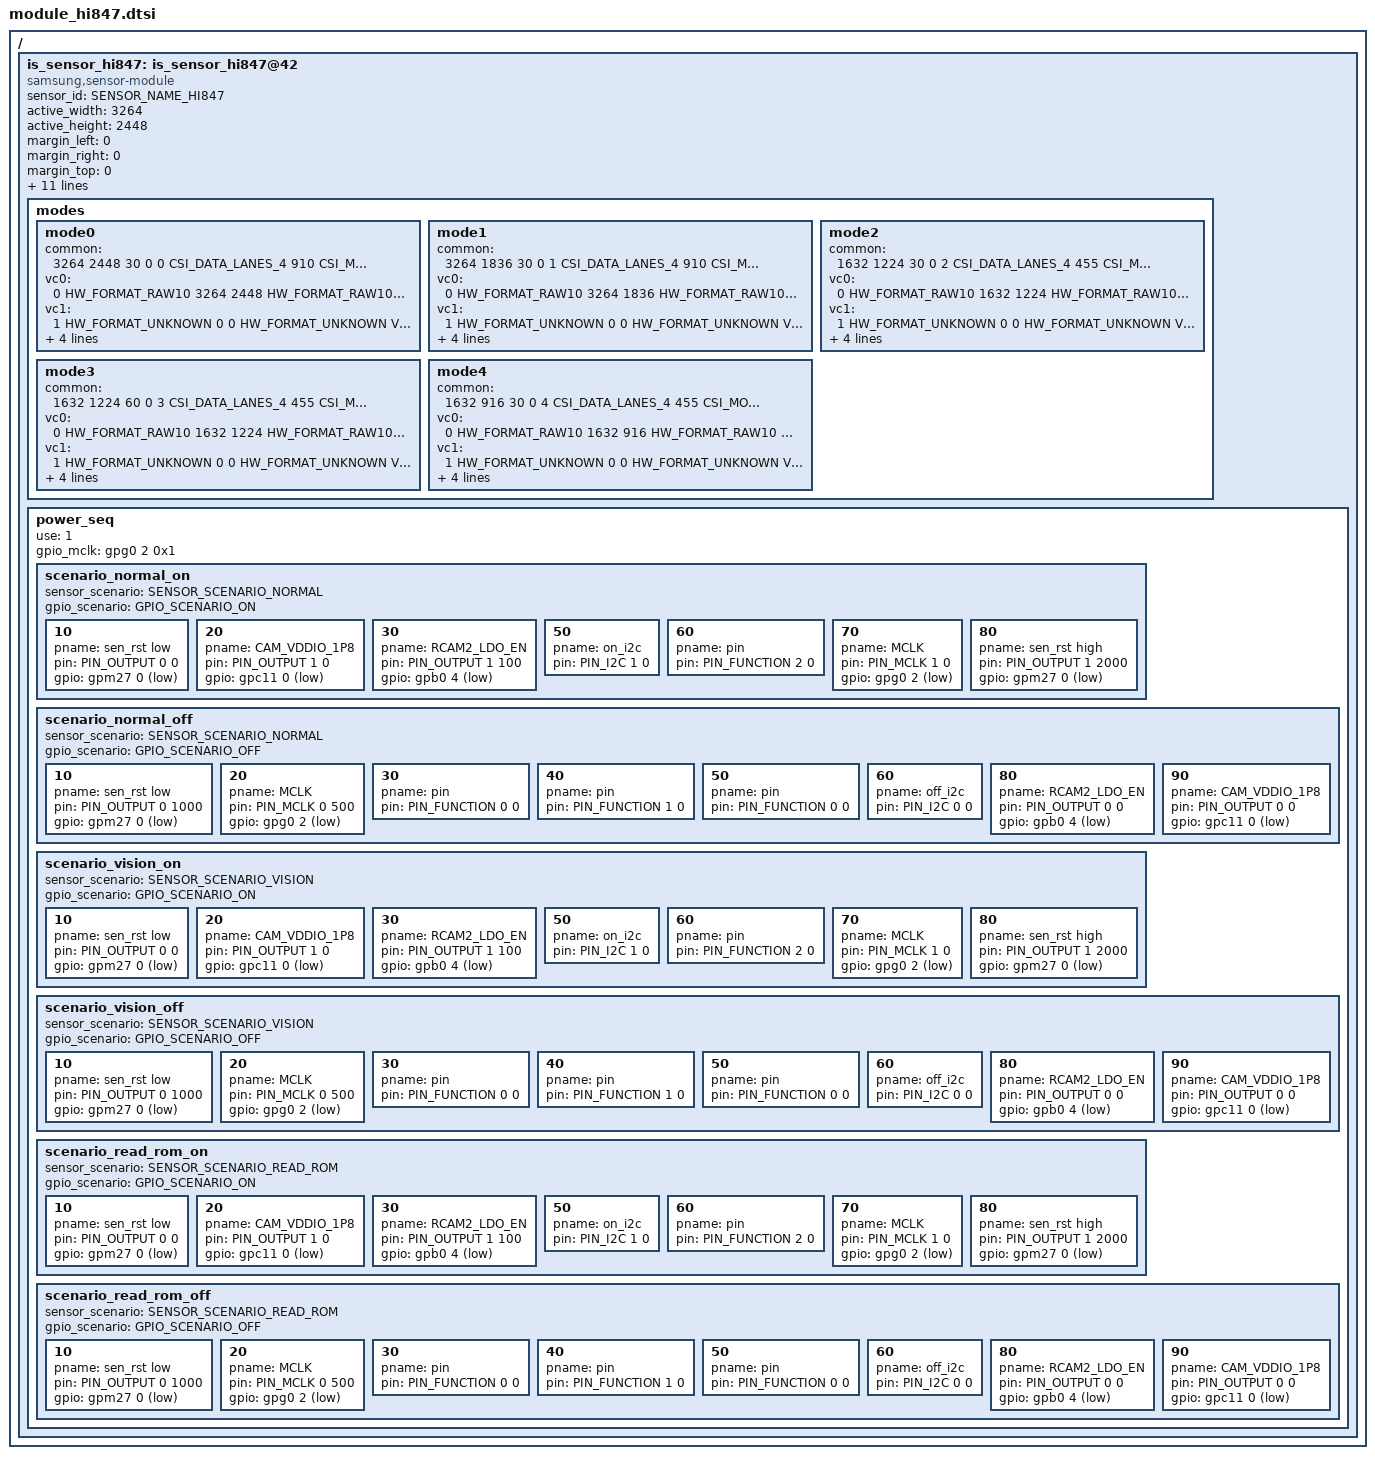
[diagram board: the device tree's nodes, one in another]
/*
 * SAMSUNG EXYNOSxxxx board camera device tree source
 *
 * Copyright (c) 2023 Samsung Electronics Co., Ltd.
 *		http://www.samsung.com
 *
 * This program is free software; you can redistribute it and/or modify
 * it under the terms of the GNU General Public License version 2 as
 * published by the Free Software Foundation.
 */

#include <dt-bindings/camera/exynos_is_dt.h>

/ {
	fragment@camera {
		target-path = "/";
		__overlay__ {
			is_sensor_hi847: is_sensor_hi847@42 {
				compatible = "samsung,sensor-module";

				/* common */
				sensor_id = <SENSOR_NAME_HI847>;
				active_width = <3264>;
				active_height = <2448>;
				margin_left = <0>;
				margin_right = <0>;
				margin_top = <0>;
				margin_bottom = <0>;
				max_framerate = <60>;
				bitwidth = <10>;
				use_retention_mode = <SENSOR_RETENTION_UNSUPPORTED>;
				sensor_maker = "HYNIX";
				sensor_name = "HI847";
				setfile_name = "setfile_hi847.bin";
				//pinning_setfile;
				//preload_setfile;

				status = "okay";

				/* vendor */
				rom_type = <3>; /* ROM_TYPE_OTPROM */
				rom_id = <2>;
				rom_cal_index = <0>;
#if 0
				vc_extra {
					/* ex) statX = <stat_type, sensor_mode, max_width, max_height, max_element> */
					/* VC_BUF_DATA_TYPE_SENSOR_STAT1 */
					stat0 = </*VC_STAT_TYPE_TAIL_FOR_3HDR_IMX_2_STAT0*/ 602    /*VC_SENSOR_MODE_3HDR_IMX_2*/ 602 4080 2 1>;
					/* VC_BUF_DATA_TYPE_GENERAL_STAT1 */
					stat1 = </* not available */>;
					/* VC_BUF_DATA_TYPE_SENSOR_STAT2 */
					stat2 = </*VC_STAT_TYPE_TAIL_FOR_3HDR_IMX_2_STAT1*/ 603    /*VC_SENSOR_MODE_3HDR_IMX_2*/ 602 4080 3 1>;
					/* VC_BUF_DATA_TYPE_GENERAL_STAT2 */
					stat3 = </* not available */>;
				};
#endif
				/*
				* [Mode Information]
				*
				* Reference File : Hi-847_setting_v1.0.0.69_SEC12_20220124.xlsx
				*
				*  [ 0 ] 3264 x 2448(4:3)      @30,  MIPI lane: 4, MIPI data rate(Mbps/lane):  910, Mclk(Mhz): 26
				*  [ 1 ] 3264 x 1836(16:9)      @30,  MIPI lane: 4, MIPI data rate(Mbps/lane):  910, Mclk(Mhz): 26
				*  [ 2 ] 1632 x 1224(4:3)      @30,  MIPI lane: 4, MIPI data rate(Mbps/lane):  455, Mclk(Mhz): 26
				*  [ 3 ] 1632 x 1224(4:3)      @60,  MIPI lane: 4, MIPI data rate(Mbps/lane):  455, Mclk(Mhz): 26
				*  [ 4 ] 1632 x 916(16:9)      @30,  MIPI lane: 4, MIPI data rate(Mbps/lane):  455, Mclk(Mhz): 26
				*/

				/* sensor modes */
				modes {
						/* common = <width, height, fps, settle, mode, lane, speed, interleave, lrte, pd_mode> */
						/* vcX = <map, hwformat, width, height, hwformat, type, width, height> */

					mode0 {/* A-1 */
						common = <3264 2448 30 0 0 CSI_DATA_LANES_4 910 CSI_MODE_VC_ONLY LRTE_DISABLE PD_NONE EX_NONE>;
						vc0 = </* in */ 0 HW_FORMAT_RAW10 3264 2448    /* out */ HW_FORMAT_RAW10 VC_NOTHING 3264 2448>;
						vc1 = </* in */ 1 HW_FORMAT_UNKNOWN 0 0        /* out */ HW_FORMAT_UNKNOWN VC_NOTHING 0 0>;
						vc2 = </* in */ 2 HW_FORMAT_UNKNOWN 0 0        /* out */ HW_FORMAT_UNKNOWN VC_NOTHING 0 0>; 
						vc3 = </* in */ 3 HW_FORMAT_UNKNOWN 0 0        /* out */ HW_FORMAT_UNKNOWN VC_NOTHING 0 0>;
					};
					mode1 {/* K-1 */
						common = <3264 1836 30 0 1 CSI_DATA_LANES_4 910 CSI_MODE_VC_ONLY LRTE_DISABLE PD_NONE>;
						vc0 = </* in */ 0 HW_FORMAT_RAW10 3264 1836    /* out */ HW_FORMAT_RAW10 VC_NOTHING 3264 1836>;
						vc1 = </* in */ 1 HW_FORMAT_UNKNOWN 0 0        /* out */ HW_FORMAT_UNKNOWN VC_NOTHING 0 0>;
						vc2 = </* in */ 2 HW_FORMAT_UNKNOWN 0 0        /* out */ HW_FORMAT_UNKNOWN VC_NOTHING 0 0>;
						vc3 = </* in */ 3 HW_FORMAT_UNKNOWN 0 0        /* out */ HW_FORMAT_UNKNOWN VC_NOTHING 0 0>;
					};
					mode2 {/* N-1 */
						common = <1632 1224 30 0 2 CSI_DATA_LANES_4 455 CSI_MODE_VC_ONLY LRTE_DISABLE PD_NONE>;
						vc0 = </* in */ 0 HW_FORMAT_RAW10 1632 1224    /* out */ HW_FORMAT_RAW10 VC_NOTHING 1632 1224>;
						vc1 = </* in */ 1 HW_FORMAT_UNKNOWN 0 0        /* out */ HW_FORMAT_UNKNOWN VC_NOTHING 0 0>;
						vc2 = </* in */ 2 HW_FORMAT_UNKNOWN 0 0        /* out */ HW_FORMAT_UNKNOWN VC_NOTHING 0 0>;
						vc3 = </* in */ 3 HW_FORMAT_UNKNOWN 0 0        /* out */ HW_FORMAT_UNKNOWN VC_NOTHING 0 0>;
					};
					mode3 {/* J-1 */
						common = <1632 1224 60 0 3 CSI_DATA_LANES_4 455 CSI_MODE_VC_ONLY LRTE_DISABLE PD_NONE>;
						vc0 = </* in */ 0 HW_FORMAT_RAW10 1632 1224    /* out */ HW_FORMAT_RAW10 VC_NOTHING 1632 1224>;
						vc1 = </* in */ 1 HW_FORMAT_UNKNOWN 0 0        /* out */ HW_FORMAT_UNKNOWN VC_NOTHING 0 0>;
						vc2 = </* in */ 2 HW_FORMAT_UNKNOWN 0 0        /* out */ HW_FORMAT_UNKNOWN VC_NOTHING 0 0>;
						vc3 = </* in */ 3 HW_FORMAT_UNKNOWN 0 0        /* out */ HW_FORMAT_UNKNOWN VC_NOTHING 0 0>;
					};
					mode4 {/* J-1 */
						common = <1632 916 30 0 4 CSI_DATA_LANES_4 455 CSI_MODE_VC_ONLY LRTE_DISABLE PD_NONE>;
						vc0 = </* in */ 0 HW_FORMAT_RAW10 1632 916    /* out */ HW_FORMAT_RAW10 VC_NOTHING 1632 916>;
						vc1 = </* in */ 1 HW_FORMAT_UNKNOWN 0 0        /* out */ HW_FORMAT_UNKNOWN VC_NOTHING 0 0>;
						vc2 = </* in */ 2 HW_FORMAT_UNKNOWN 0 0        /* out */ HW_FORMAT_UNKNOWN VC_NOTHING 0 0>;
						vc3 = </* in */ 3 HW_FORMAT_UNKNOWN 0 0        /* out */ HW_FORMAT_UNKNOWN VC_NOTHING 0 0>;
					};
				};

				power_seq {
					use = <1>;
					gpio_mclk = <&gpg0 2 0x1>;

					scenario_normal_on {
						sensor_scenario = <SENSOR_SCENARIO_NORMAL>;
						gpio_scenario = <GPIO_SCENARIO_ON>;

						/* A start node number should be over the 10 for reserved number 0~9. */
						/* pname = "name"; pin = <act value dealy voltage>; gpio = <gpx# # 0x1>; */
						10 { pname = "sen_rst low"; pin = <PIN_OUTPUT 0 0>; gpio = <&gpm27 0 0x1>; };
						20 { pname = "CAM_VDDIO_1P8"; pin = <PIN_OUTPUT 1 0>; gpio = <&gpc11 0 0x1>; };
						30 { pname = "RCAM2_LDO_EN"; pin = <PIN_OUTPUT 1 100>; gpio = <&gpb0 4 0x1>; };
						50 { pname = "on_i2c"; pin = <PIN_I2C 1 0>; };
						60 { pname = "pin"; pin = <PIN_FUNCTION 2 0>; };
						70 { pname = "MCLK"; pin = <PIN_MCLK 1 0>; gpio = <&gpg0 2 0x1>; };
						80 { pname = "sen_rst high"; pin = <PIN_OUTPUT 1 2000>; gpio = <&gpm27 0 0x1>; };
					};

					scenario_normal_off {
						sensor_scenario = <SENSOR_SCENARIO_NORMAL>;
						gpio_scenario = <GPIO_SCENARIO_OFF>;

						/* A start node number should be over the 10 for reserved number 0~9. */
						/* pname = "name"; pin = <act value dealy voltage>; gpio = <gpx# # 0x1>; */
						10 { pname = "sen_rst low"; pin = <PIN_OUTPUT 0 1000>; gpio = <&gpm27 0 0x1>; };
						20 { pname = "MCLK"; pin = <PIN_MCLK 0 500>; gpio = <&gpg0 2 0x1>; };
						30 { pname = "pin"; pin = <PIN_FUNCTION 0 0>; };
						40 { pname = "pin"; pin = <PIN_FUNCTION 1 0>; };
						50 { pname = "pin"; pin = <PIN_FUNCTION 0 0>; };
						60 { pname = "off_i2c"; pin = <PIN_I2C 0 0>; };
						80 { pname = "RCAM2_LDO_EN"; pin = <PIN_OUTPUT 0 0>; gpio = <&gpb0 4 0x1>; };
						90 { pname = "CAM_VDDIO_1P8"; pin = <PIN_OUTPUT 0 0>;  gpio = <&gpc11 0 0x1>;};
					};
					scenario_vision_on {
						sensor_scenario = <SENSOR_SCENARIO_VISION>;
						gpio_scenario = <GPIO_SCENARIO_ON>;

						/* A start node number should be over the 10 for reserved number 0~9. */
						/* pname = "name"; pin = <act value dealy voltage>; gpio = <gpx# # 0x1>; */
						10 { pname = "sen_rst low"; pin = <PIN_OUTPUT 0 0>; gpio = <&gpm27 0 0x1>; };
						20 { pname = "CAM_VDDIO_1P8"; pin = <PIN_OUTPUT 1 0>; gpio = <&gpc11 0 0x1>; };
						30 { pname = "RCAM2_LDO_EN"; pin = <PIN_OUTPUT 1 100>; gpio = <&gpb0 4 0x1>; };
						50 { pname = "on_i2c"; pin = <PIN_I2C 1 0>; };
						60 { pname = "pin"; pin = <PIN_FUNCTION 2 0>; };
						70 { pname = "MCLK"; pin = <PIN_MCLK 1 0>; gpio = <&gpg0 2 0x1>; };
						80 { pname = "sen_rst high"; pin = <PIN_OUTPUT 1 2000>; gpio = <&gpm27 0 0x1>; };
					};

					scenario_vision_off {
						sensor_scenario = <SENSOR_SCENARIO_VISION>;
						gpio_scenario = <GPIO_SCENARIO_OFF>;

						/* A start node number should be over the 10 for reserved number 0~9. */
						/* pname = "name"; pin = <act value dealy voltage>; gpio = <gpx# # 0x1>; */
						10 { pname = "sen_rst low"; pin = <PIN_OUTPUT 0 1000>; gpio = <&gpm27 0 0x1>; };
						20 { pname = "MCLK"; pin = <PIN_MCLK 0 500>; gpio = <&gpg0 2 0x1>; };
						30 { pname = "pin"; pin = <PIN_FUNCTION 0 0>; };
						40 { pname = "pin"; pin = <PIN_FUNCTION 1 0>; };
						50 { pname = "pin"; pin = <PIN_FUNCTION 0 0>; };
						60 { pname = "off_i2c"; pin = <PIN_I2C 0 0>; };
						80 { pname = "RCAM2_LDO_EN"; pin = <PIN_OUTPUT 0 0>; gpio = <&gpb0 4 0x1>; };
						90 { pname = "CAM_VDDIO_1P8"; pin = <PIN_OUTPUT 0 0>;  gpio = <&gpc11 0 0x1>;};
					};

					scenario_read_rom_on {
						sensor_scenario = <SENSOR_SCENARIO_READ_ROM>;
						gpio_scenario = <GPIO_SCENARIO_ON>;

						/* A start node number should be over the 10 for reserved number 0~9. */
						/* pname = "name"; pin = <act value dealy voltage>; gpio = <gpx# # 0x1>; */
						10 { pname = "sen_rst low"; pin = <PIN_OUTPUT 0 0>; gpio = <&gpm27 0 0x1>; };
						20 { pname = "CAM_VDDIO_1P8"; pin = <PIN_OUTPUT 1 0>; gpio = <&gpc11 0 0x1>; };
						30 { pname = "RCAM2_LDO_EN"; pin = <PIN_OUTPUT 1 100>; gpio = <&gpb0 4 0x1>; };
						50 { pname = "on_i2c"; pin = <PIN_I2C 1 0>; };
						60 { pname = "pin"; pin = <PIN_FUNCTION 2 0>; };
						70 { pname = "MCLK"; pin = <PIN_MCLK 1 0>; gpio = <&gpg0 2 0x1>; };
						80 { pname = "sen_rst high"; pin = <PIN_OUTPUT 1 2000>; gpio = <&gpm27 0 0x1>; };
					};

					scenario_read_rom_off {
						sensor_scenario = <SENSOR_SCENARIO_READ_ROM>;
						gpio_scenario = <GPIO_SCENARIO_OFF>;

						/* A start node number should be over the 10 for reserved number 0~9. */
						/* pname = "name"; pin = <act value dealy voltage>; gpio = <gpx# # 0x1>; */
						10 { pname = "sen_rst low"; pin = <PIN_OUTPUT 0 1000>; gpio = <&gpm27 0 0x1>; };
						20 { pname = "MCLK"; pin = <PIN_MCLK 0 500>; gpio = <&gpg0 2 0x1>; };
						30 { pname = "pin"; pin = <PIN_FUNCTION 0 0>; };
						40 { pname = "pin"; pin = <PIN_FUNCTION 1 0>; };
						50 { pname = "pin"; pin = <PIN_FUNCTION 0 0>; };
						60 { pname = "off_i2c"; pin = <PIN_I2C 0 0>; };
						80 { pname = "RCAM2_LDO_EN"; pin = <PIN_OUTPUT 0 0>; gpio = <&gpb0 4 0x1>; };
						90 { pname = "CAM_VDDIO_1P8"; pin = <PIN_OUTPUT 0 0>;  gpio = <&gpc11 0 0x1>;};
					};
				};
			};
		}; /* end of __overlay__ */
	}; /* end of fragment */
}; /* end of root */
